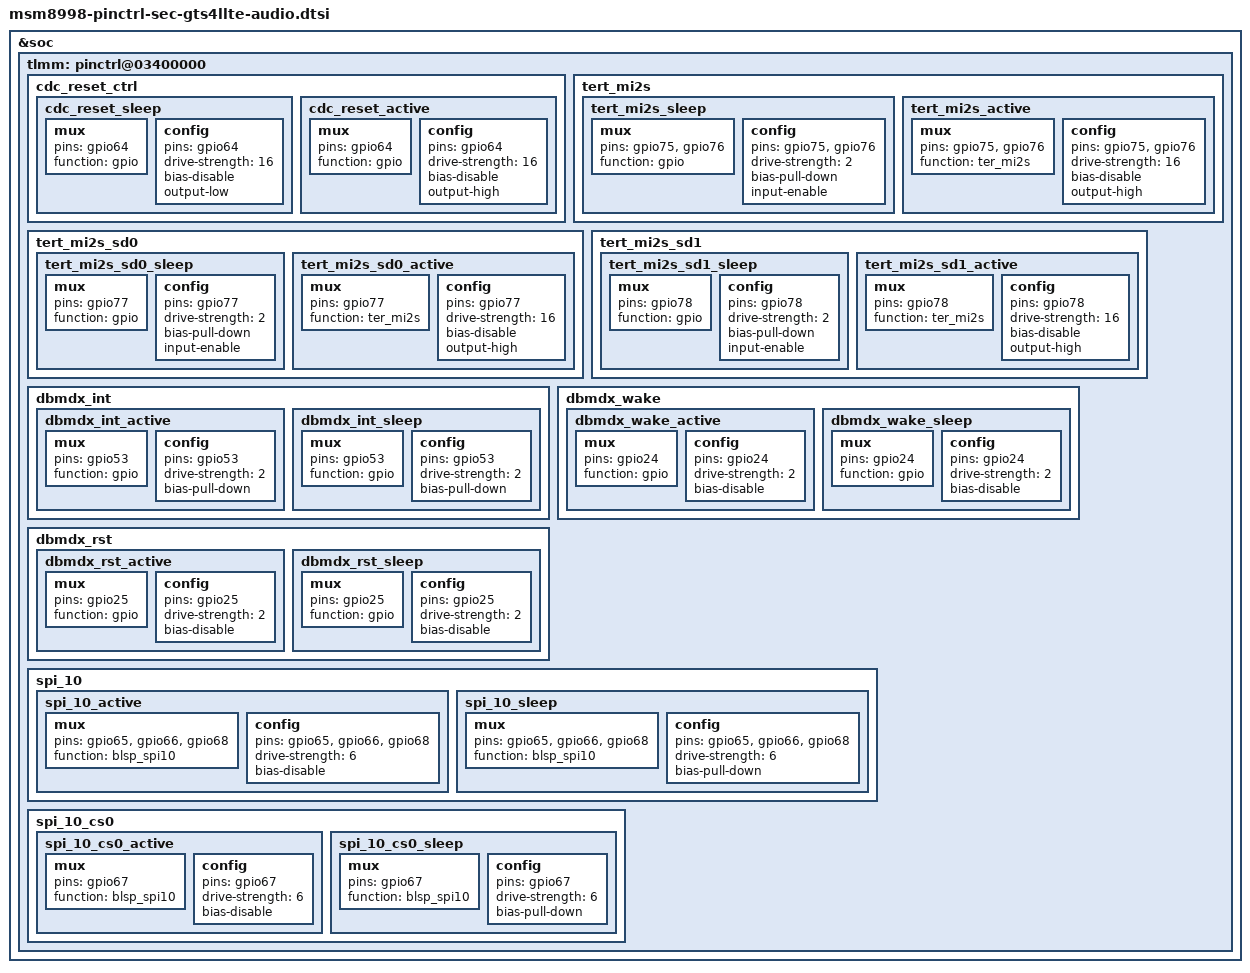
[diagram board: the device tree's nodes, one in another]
/* Copyright (c) 2015-2016, The Linux Foundation. All rights reserved.
 *
 * This program is free software; you can redistribute it and/or modify
 * it under the terms of the GNU General Public License version 2 and
 * only version 2 as published by the Free Software Foundation.
 *
 * This program is distributed in the hope that it will be useful,
 * but WITHOUT ANY WARRANTY; without even the implied warranty of
 * MERCHANTABILITY or FITNESS FOR A PARTICULAR PURPOSE.  See the
 * GNU General Public License for more details.
 */

&soc {
	tlmm: pinctrl@03400000 {
		/delete-node/wcd_gnd_mic_swap;
		/delete-node/spkr_1_sd_n;
		/delete-node/spkr_2_sd_n;

		/delete-node/cdc_reset_ctrl;
		cdc_reset_ctrl {
			cdc_reset_sleep: cdc_reset_sleep {
				mux {
					pins = "gpio64";
					function = "gpio";
				};
				config {
					pins = "gpio64";
					drive-strength = <16>;
					bias-disable;
					output-low;
				};
			};
			cdc_reset_active:cdc_reset_active {
				mux {
					pins = "gpio64";
					function = "gpio";
				};
				config {
					pins = "gpio64";
					drive-strength = <16>;
					bias-disable;
					output-high;
				};
			};
		};

		tert_mi2s {
			tert_mi2s_sleep: tert_mi2s_sleep {
				mux {
					pins = "gpio75", "gpio76";
					function = "gpio";
				};

				config {
					pins = "gpio75", "gpio76";
					drive-strength = <2>;   /* 2 mA */
					bias-pull-down;         /* PULL DOWN */
					input-enable;
				};
			};
			tert_mi2s_active: tert_mi2s_active {
				mux {
					pins = "gpio75", "gpio76";
					function = "ter_mi2s";
				};

				config {
					pins = "gpio75", "gpio76";
					drive-strength = <16>;   /* 8 mA */
					bias-disable;           /* NO PULL */
					output-high;
				};
			};
		};

		tert_mi2s_sd0 {
			tert_mi2s_sd0_sleep: tert_mi2s_sd0_sleep {
				mux {
					pins = "gpio77";
					function = "gpio";
				};

				config {
					pins = "gpio77";
					drive-strength = <2>;   /* 2 mA */
					bias-pull-down;         /* PULL DOWN */
					input-enable;
				};
			};
			tert_mi2s_sd0_active: tert_mi2s_sd0_active {
				mux {
					pins = "gpio77";
					function = "ter_mi2s";
				};

				config {
					pins = "gpio77";
					drive-strength = <16>;   /* 8 mA */
					bias-disable;           /* NO PULL */
					output-high;
				};
			};
		};

		tert_mi2s_sd1 {
			tert_mi2s_sd1_sleep: tert_mi2s_sd1_sleep {
				mux {
					pins = "gpio78";
					function = "gpio";
				};

				config {
					pins = "gpio78";
					drive-strength = <2>;   /* 2 mA */
					bias-pull-down;         /* PULL DOWN */
					input-enable;
				};
			};
			tert_mi2s_sd1_active: tert_mi2s_sd1_active {
				mux {
					pins = "gpio78";
					function = "ter_mi2s";
				};

				config {
					pins = "gpio78";
					drive-strength = <16>;   /* 8 mA */
					bias-disable;           /* NO PULL */
					output-high;
				};
			};
		};

		dbmdx_int {
			dbmdx_int_active: dbmdx_int_active {
				mux {
					pins = "gpio53";
					function = "gpio";
				};
				config {
					pins = "gpio53";
					drive-strength = <2>;
					bias-pull-down;
				};
			};

			dbmdx_int_sleep: dbmdx_int_sleep {
				mux {
					pins = "gpio53";
					function = "gpio";
				};
				config {
					pins = "gpio53";
					drive-strength = <2>;
					bias-pull-down;
				};
			};
		};

		dbmdx_wake {
			dbmdx_wake_active: dbmdx_wake_active {
				mux {
					pins = "gpio24";
					function = "gpio";
				};
				config {
					pins = "gpio24";
					drive-strength = <2>;
					bias-disable;
				};
			};

			dbmdx_wake_sleep: dbmdx_wake_sleep {
				mux {
					pins = "gpio24";
					function = "gpio";
				};
				config {
					pins = "gpio24";
					drive-strength = <2>;
					bias-disable;
				};
			};
		};

		dbmdx_rst {
			dbmdx_rst_active: dbmdx_rst_active {
				mux {
					pins = "gpio25";
					function = "gpio";
				};
				config {
					pins = "gpio25";
					drive-strength = <2>;
					bias-disable;
				};
			};

			dbmdx_rst_sleep: dbmdx_rst_sleep {
				mux {
					pins = "gpio25";
					function = "gpio";
				};
				config {
					pins = "gpio25";
					drive-strength = <2>;
					bias-disable;
				};
			};
		};

		spi_10 {
			spi_10_active: spi_10_active {
				mux {
					pins = "gpio65", "gpio66", "gpio68";
					function = "blsp_spi10";
				};

				config {
					pins = "gpio65", "gpio66", "gpio68";
					drive-strength = <6>;
					bias-disable;
				};
			};

			spi_10_sleep: spi_10_sleep {
				mux {
					pins = "gpio65", "gpio66", "gpio68";
					function = "blsp_spi10";
				};

				config {
					pins = "gpio65", "gpio66", "gpio68";
					drive-strength = <6>;
					bias-pull-down;
				};
			};
		};

		spi_10_cs0 {
			/* CS0 */
			spi_10_cs0_active: spi_10_cs0_active {
				mux {
					pins = "gpio67";
					function = "blsp_spi10";
				};
				config {
					pins = "gpio67";
					drive-strength = <6>;
					bias-disable;
				};
			};

			spi_10_cs0_sleep: spi_10_cs0_sleep {
				mux {
					pins = "gpio67";
					function = "blsp_spi10";
				};
				config {
					pins = "gpio67";
					drive-strength = <6>;
					bias-pull-down;
				};
			};
		};
	};
};
